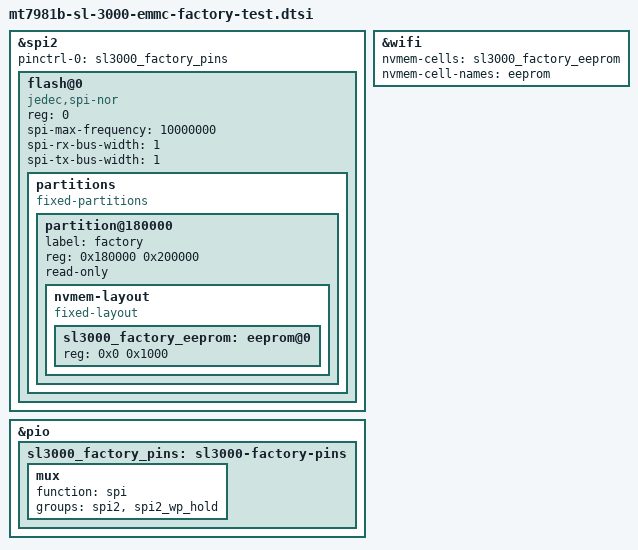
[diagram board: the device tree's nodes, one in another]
// SPDX-License-Identifier: GPL-2.0-or-later OR MIT
// SPI2 wiring: OpenWrt PR 24172. Factory layout also checked against live NOR.
// No per-device bytes: each router supplies its own calibration at boot.
&spi2 {
	pinctrl-names = "default";
	pinctrl-0 = <&sl3000_factory_pins>;
	status = "okay";

	flash@0 {
		compatible = "jedec,spi-nor";
		reg = <0>;
		spi-max-frequency = <10000000>;
		spi-rx-bus-width = <1>;
		spi-tx-bus-width = <1>;

		partitions {
			compatible = "fixed-partitions";
			#address-cells = <1>;
			#size-cells = <1>;

			partition@180000 {
				label = "factory";
				reg = <0x180000 0x200000>;
				read-only;

				nvmem-layout {
					compatible = "fixed-layout";
					#address-cells = <1>;
					#size-cells = <1>;

					sl3000_factory_eeprom: eeprom@0 {
						reg = <0x0 0x1000>;
					};
				};
			};
		};
	};
};

&pio {
	sl3000_factory_pins: sl3000-factory-pins {
		mux {
			function = "spi";
			groups = "spi2", "spi2_wp_hold";
		};
	};
};

&wifi {
	nvmem-cells = <&sl3000_factory_eeprom>;
	nvmem-cell-names = "eeprom";
};
